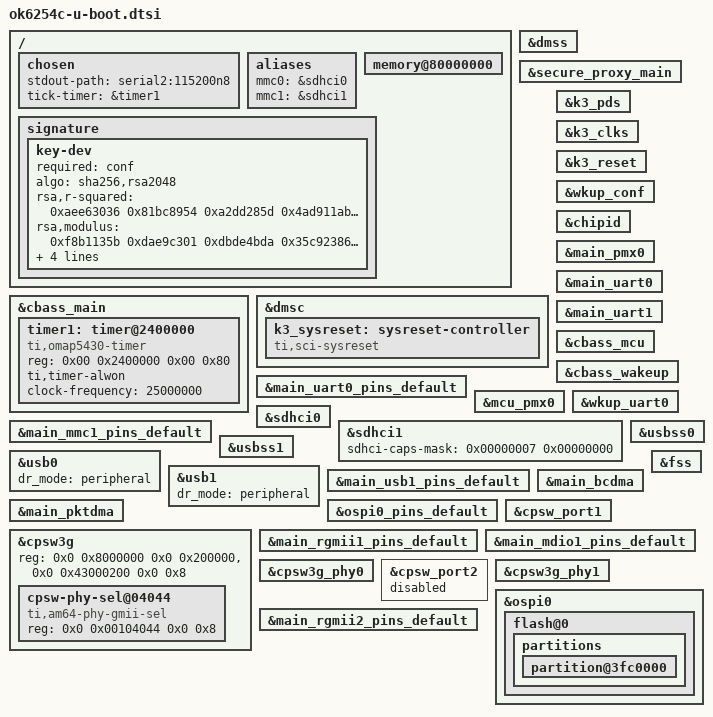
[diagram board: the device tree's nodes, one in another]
// SPDX-License-Identifier: GPL-2.0
/*
 * ok6254c dts file for SPLs
 *  Copyright (C) 2022 UWINGS TECHNOLOGIES
 *	KunYi Chen <kunyi.chen@gmail.com>
 */

/ {
	chosen {
		stdout-path = "serial2:115200n8";
		tick-timer = &timer1;
	};

	aliases {
		mmc0 = &sdhci0;
		mmc1 = &sdhci1;
	};

	memory@80000000 {
		u-boot,dm-spl;
	};

	signature {

		key-dev {
			required = "conf";
			algo = "sha256,rsa2048";
			rsa,r-squared = <0xaee63036 0x81bc8954 0xa2dd285d 0x4ad911ab 0xfae5e634 0x7af74025 0x67138e57 0xdcfdc3e0 0x2404de27 0xc57c69f0 0xa2e40293 0x3093c75b 0x2cf1db78 0x6044b28a 0xe2b77219 0x30432f40 0x573b507b 0xc8421a5a 0xe4dea5fd 0x50297989 0xd68fe174 0x9a91e956 0x9c040341 0xb40d8bc2 0x8ac1057f 0x7dce3148 0x1f82e14 0x482cb91b 0xb4b6fa73 0x58c03490 0x29af65e8 0xe7b456 0x4e75158a 0x1328694 0x51a6381c 0xa506fc4c 0xe24bb771 0x113dbf4f 0x31ec61bf 0xbb817b85 0x8ffab285 0xecab4f0c 0xdd414310 0xd58046f0 0xe8dbb834 0xfe9d0c5e 0xac0b83b2 0x9f32c020 0x24dc0fa4 0x429f59c3 0x56894fce 0xe09f2b14 0xe14dee4f 0xeab296b4 0x53c96da3 0x2b9d12cd 0x99a684a4 0x4158bb69 0x94550b5a 0x19d857b8 0xfb0e4431 0xd8955c 0x3a6a3ef3 0x45a58566>;
			rsa,modulus = <0xf8b1135b 0xdae9c301 0xdbde4bda 0x35c92386 0xf837636b 0x894fda4b 0xe1ab54da 0x69438f87 0x28ec28e0 0x50821e42 0x8ebed3a5 0x78f3fed6 0x1c9b1af0 0xe835032d 0xbc0f64fe 0x6682bf9 0x804c82b6 0xdb0cb4a 0x59e7426e 0xe38a7851 0xb490799 0x12f0fe6 0x4dabe5d1 0x2a57948a 0x4fbf812f 0x5eee2152 0x94643f57 0xcdbe392e 0x5f691298 0x3cc022be 0x9df7a492 0x9b39eeb9 0x7847ec59 0x8e98cb85 0x34c5891a 0xc4066358 0xaedcbd39 0x2c3a65a3 0xb04131ff 0x32f1eea 0x52c8613a 0xd7a69eef 0x179f764c 0x1641fbe6 0x4c61a33a 0xd16fe8bc 0x67111c56 0x1ec77715 0x123e3721 0x2b5389af 0xef562f8f 0x7e7281ed 0x59495546 0xdef41586 0x4b5ac752 0xfa6b1c75 0x89346bc0 0xa0de32f3 0x2d1f9f68 0xc8d11fa1 0xb6c15c5b 0x4eada061 0xc090fff2 0x4cba2f31>;
			rsa,exponent = <0x00 0x10001>;
			rsa,n0-inverse = <0x4c6d362f>;
			rsa,num-bits = <0x800>;
			key-name-hint = "dev";
		};
	};
};

&cbass_main{
	u-boot,dm-spl;

	timer1: timer@2400000 {
		compatible = "ti,omap5430-timer";
		reg = <0x00 0x2400000 0x00 0x80>;
		ti,timer-alwon;
		clock-frequency = <25000000>;
		u-boot,dm-spl;
	};
};

&dmss {
	u-boot,dm-spl;
};

&secure_proxy_main {
	u-boot,dm-spl;
};

&dmsc {
	u-boot,dm-spl;
};

&k3_pds {
	u-boot,dm-spl;
};

&k3_clks {
	u-boot,dm-spl;
};

&k3_reset {
	u-boot,dm-spl;
};

&wkup_conf {
	u-boot,dm-spl;
};

&chipid {
	u-boot,dm-spl;
};

&main_pmx0 {
	u-boot,dm-spl;
};

&main_uart0 {
	u-boot,dm-spl;
};

&main_uart0_pins_default {
	u-boot,dm-spl;
};

&main_uart1 {
	u-boot,dm-spl;
};

&cbass_mcu {
	u-boot,dm-spl;
};

&cbass_wakeup {
	u-boot,dm-spl;
};

&mcu_pmx0 {
	u-boot,dm-spl;
};

&wkup_uart0 {
	u-boot,dm-spl;
};

&sdhci0 {
	u-boot,dm-spl;
};

&sdhci1 {
	sdhci-caps-mask = <0x00000007 0x00000000>;
	u-boot,dm-spl;
};

&main_mmc1_pins_default {
	u-boot,dm-spl;
};

&usbss0 {
	u-boot,dm-spl;
};

&usb0 {
	dr_mode = "peripheral";
	/* Since role switching is not supported in U-Boot */
	/delete-property/ extcon;
	u-boot,dm-spl;
};

&usbss1 {
	u-boot,dm-spl;
};

&usb1 {
	dr_mode = "peripheral";
	/* Since role switching is not supported in U-Boot */
	/delete-property/ extcon;
	u-boot,dm-spl;
};

&main_usb1_pins_default {
	u-boot,dm-spl;
};

&main_bcdma {
	u-boot,dm-spl;
};

&main_pktdma {
	u-boot,dm-spl;
};

&fss {
	u-boot,dm-spl;
};

&ospi0_pins_default {
	u-boot,dm-spl;
};

&cpsw3g {
	reg = <0x0 0x8000000 0x0 0x200000>,
	      <0x0 0x43000200 0x0 0x8>;
	reg-names = "cpsw_nuss", "mac_efuse";
	/delete-property/ ranges;
	u-boot,dm-spl;

	cpsw-phy-sel@04044 {
		compatible = "ti,am64-phy-gmii-sel";
		reg = <0x0 0x00104044 0x0 0x8>;
		u-boot,dm-spl;
	};
};

&cpsw_port1 {
	u-boot,dm-spl;
};

&main_rgmii1_pins_default {
	u-boot,dm-spl;
};

&main_mdio1_pins_default {
	u-boot,dm-spl;
};

&cpsw3g_phy0 {
	u-boot,dm-spl;
};

&cpsw_port2 {
	u-boot,dm-spl;
	status = "disabled";
};

&main_rgmii2_pins_default {
	u-boot,dm-spl;
};

&cpsw3g_phy1 {
	u-boot,dm-spl;
};

&dmsc {
	u-boot,dm-spl;
	k3_sysreset: sysreset-controller {
		compatible = "ti,sci-sysreset";
		u-boot,dm-spl;
	};
};



&ospi0 {
	u-boot,dm-spl;

	flash@0 {
		u-boot,dm-spl;

		partitions {
			u-boot,dm-spl;

			partition@3fc0000 {
				u-boot,dm-spl;
			};
		};
	};
};
